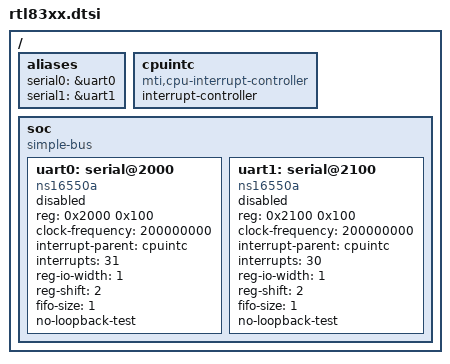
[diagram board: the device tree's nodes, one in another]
// SPDX-License-Identifier: GPL-2.0-or-later OR BSD-2-Clause

/ {
	#address-cells = <1>;
	#size-cells = <1>;

	aliases {
		serial0 = &uart0;
		serial1 = &uart1;
	};

	cpuintc: cpuintc {
		compatible = "mti,cpu-interrupt-controller";
		#address-cells = <0>;
		#interrupt-cells = <1>;
		interrupt-controller;
	};

	soc: soc {
		compatible = "simple-bus";
		#address-cells = <1>;
		#size-cells = <1>;
		ranges = <0x0 0x18000000 0x10000>;

		uart0: serial@2000 {
			compatible = "ns16550a";
			reg = <0x2000 0x100>;

			clock-frequency = <200000000>;

			interrupt-parent = <&cpuintc>;
			interrupts = <31>;

			reg-io-width = <1>;
			reg-shift = <2>;
			fifo-size = <1>;
			no-loopback-test;

			status = "disabled";
		};

		uart1: serial@2100 {
			compatible = "ns16550a";
			reg = <0x2100 0x100>;

			clock-frequency = <200000000>;

			interrupt-parent = <&cpuintc>;
			interrupts = <30>;

			reg-io-width = <1>;
			reg-shift = <2>;
			fifo-size = <1>;
			no-loopback-test;

			status = "disabled";
		};
	};
};
